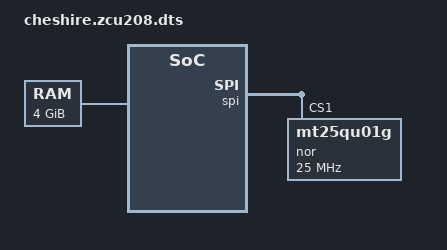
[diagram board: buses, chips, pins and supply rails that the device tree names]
// Copyright 2024 ETH Zurich and University of Bologna.
// Solderpad Hardware License, Version 0.51, see LICENSE for details.
// SPDX-License-Identifier: SHL-0.51
//
// Cyril Koenig <cykoenig@iis.ee.ethz.ch>

/include/ "cheshire.dtsi"

/ {
  chosen {
    bootargs = "console=ttyS0,115200 earlycon=uart8250,mmio32,0x3002000 random.trust_cpu=on rw";
  };

  memory@80000000 {
    device_type = "memory";
    reg = <0x0 0x80000000 0x1 0x00000000>; // 4GB
  };
};

&PLIC0 {
  compatible = "sifive,plic-1.0.0", "riscv,plic0";
  riscv,ndev = <58>;
};

&soc {
  serial@3002000 {
    interrupts = <1>;
  };
};

&spi {
  boot-with = <2>; // 2 for SD Card (CS0)
  nor@1 {
    compatible = "mt25qu01g", "jedec,spi-nor";
    reg = <0x1>; // CS1
    spi-max-frequency = <25000000>;
    disable-wp;
  };
};
